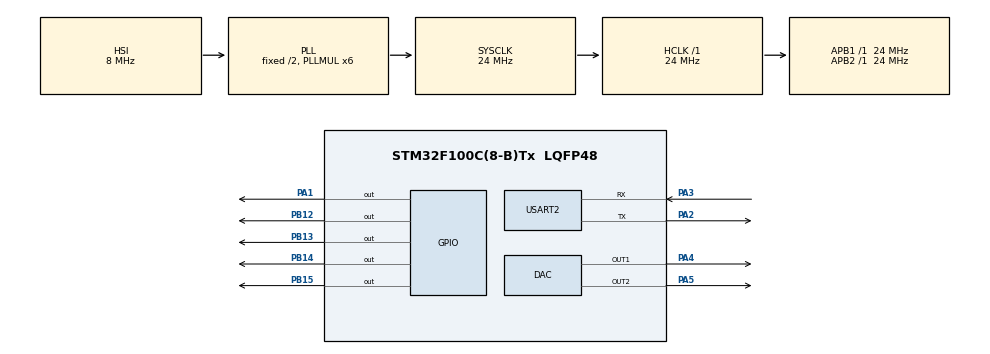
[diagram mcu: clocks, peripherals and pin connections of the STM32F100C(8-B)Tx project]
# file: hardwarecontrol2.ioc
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Dma.Request0=USART2_RX
Dma.Request1=USART2_TX
Dma.USART2_RX.0.Direction=DMA_PERIPH_TO_MEMORY
Dma.USART2_RX.0.Instance=DMA1_Channel6
Dma.USART2_RX.0.MemDataAlignment=DMA_MDATAALIGN_BYTE
Dma.USART2_RX.0.MemInc=DMA_MINC_ENABLE
Dma.USART2_RX.0.Mode=DMA_CIRCULAR
Dma.USART2_RX.0.PeriphDataAlignment=DMA_PDATAALIGN_BYTE
Dma.USART2_RX.0.PeriphInc=DMA_PINC_DISABLE
Dma.USART2_RX.0.Priority=DMA_PRIORITY_LOW
Dma.USART2_TX.1.Direction=DMA_MEMORY_TO_PERIPH
Dma.USART2_TX.1.Instance=DMA1_Channel7
Dma.USART2_TX.1.MemDataAlignment=DMA_MDATAALIGN_BYTE
Dma.USART2_TX.1.MemInc=DMA_MINC_ENABLE
Dma.USART2_TX.1.Mode=DMA_NORMAL
Dma.USART2_TX.1.PeriphDataAlignment=DMA_PDATAALIGN_BYTE
Dma.USART2_TX.1.PeriphInc=DMA_PINC_DISABLE
Dma.USART2_TX.1.Priority=DMA_PRIORITY_LOW
Mcu.Family=STM32F1
Mcu.Name=STM32F100C(8-B)Tx
Mcu.Package=LQFP48
NVIC.DMA1_Channel6_IRQn=true\:0\:0\:false\:false\:true\:false\:true\:true
NVIC.DMA1_Channel7_IRQn=true\:0\:0\:false\:false\:true\:false\:true\:true
NVIC.PriorityGroup=NVIC_PRIORITYGROUP_4
NVIC.RCC_IRQn=true\:0\:0\:false\:false\:true\:true\:false\:true
NVIC.TIM1_TRG_COM_TIM17_IRQn=true\:0\:0\:false\:false\:true\:true\:true\:true
NVIC.TIM1_UP_TIM16_IRQn=true\:0\:0\:false\:false\:true\:true\:true\:true
NVIC.TIM7_IRQn=true\:15\:0\:false\:false\:true\:false\:true\:true
NVIC.TimeBase=TIM7_IRQn
NVIC.TimeBaseIP=TIM7
NVIC.USART2_IRQn=true\:0\:0\:false\:false\:true\:true\:true\:true
PA1.Signal=GPIO_Output
PA13.Mode=Serial_Wire
PA13.Signal=SYS_JTMS-SWDIO
PA14.Mode=Serial_Wire
PA14.Signal=SYS_JTCK-SWCLK
PA2.Mode=Asynchronous
PA2.Signal=USART2_TX
PA3.Mode=Asynchronous
PA3.Signal=USART2_RX
PA4.Signal=COMP_DAC1_group
PA5.Signal=COMP_DAC2_group
PB12.Signal=GPIO_Output
PB13.Signal=GPIO_Output
PB14.Signal=GPIO_Output
PB15.Signal=GPIO_Output
PD0-OSC_IN.Mode=HSE-External-Oscillator
PD0-OSC_IN.Signal=RCC_OSC_IN
PD1-OSC_OUT.Mode=HSE-External-Oscillator
PD1-OSC_OUT.Signal=RCC_OSC_OUT
ProjectManager.HeapSize=0x400
ProjectManager.StackSize=0x400
ProjectManager.TargetToolchain=STM32CubeIDE
RCC.AHBFreq_Value=24000000
RCC.APB1Freq_Value=24000000
RCC.APB1TimFreq_Value=24000000
RCC.APB2Freq_Value=24000000
RCC.APB2TimFreq_Value=24000000
RCC.HCLKFreq_Value=24000000
RCC.PLLMUL=RCC_PLL_MUL6
RCC.SYSCLKFreq_VALUE=24000000
RCC.SYSCLKSource=RCC_SYSCLKSOURCE_PLLCLK
SH.COMP_DAC1_group.0=DAC_OUT1,DAC_OUT1
SH.COMP_DAC2_group.0=DAC_OUT2,DAC_OUT2
USART2.VirtualMode=VM_ASYNC
VP_SYS_VS_tim7.Mode=TIM7
VP_TIM16_VS_ClockSourceINT.Mode=Enable_Timer
VP_TIM17_VS_ClockSourceINT.Mode=Enable_Timer
board=custom

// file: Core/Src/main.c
/* USER CODE BEGIN Header */
/**
  ******************************************************************************
  * @file           : main.c
  * @brief          : Main program body
  ******************************************************************************
  * @attention
  *
  * Copyright (c) 2022 STMicroelectronics.
  * All rights reserved.
  *
  * This software is licensed under terms that can be found in the LICENSE file
  * in the root directory of this software component.
  * If no LICENSE file comes with this software, it is provided AS-IS.
  *
  ******************************************************************************
  */
/* USER CODE END Header */
#include "main.h"

/* USER CODE BEGIN Includes */
#include "kernel.h"
#include "soft_timer.h"
#include "communication_facade.h"
#include "movement_driver.h"
/* USER CODE END Includes */

DAC_HandleTypeDef hdac;

TIM_HandleTypeDef htim16;
TIM_HandleTypeDef htim17;

UART_HandleTypeDef huart2;
DMA_HandleTypeDef hdma_usart2_rx;
DMA_HandleTypeDef hdma_usart2_tx;

void SystemClock_Config(void);
static void MX_GPIO_Init(void);
static void MX_DAC_Init(void);
static void MX_TIM16_Init(void);
static void MX_DMA_Init(void);
static void MX_USART2_UART_Init(void);
static void MX_TIM17_Init(void);

int main(void)
{

  /* MCU Configuration--------------------------------------------------------*/

  /* Reset of all peripherals, Initializes the Flash interface and the Systick. */
  HAL_Init();

  /* Configure the system clock */
  SystemClock_Config();

  /* Initialize all configured peripherals */
  MX_GPIO_Init();
  MX_DAC_Init();
  MX_TIM16_Init();
  MX_DMA_Init();
  MX_USART2_UART_Init();
  MX_TIM17_Init();

  /* Infinite loop */
  /* USER CODE BEGIN WHILE */
  HAL_SetTickFreq(HAL_TICK_FREQ_1KHZ);
  communicationInit(&huart2, &hdma_usart2_rx, &hdma_usart2_tx);
  KERNEL_Init();
  MovementDriver_Init(&hdac);

  while (1) {

      invokePendingTimers();
      communicationInvoke();
	  KERNEL_Check();
    /* USER CODE END WHILE */

  }
}

void SystemClock_Config(void)
{
  RCC_OscInitTypeDef RCC_OscInitStruct = {0};
  RCC_ClkInitTypeDef RCC_ClkInitStruct = {0};

  /** Initializes the RCC Oscillators according to the specified parameters
  * in the RCC_OscInitTypeDef structure.
  */
  RCC_OscInitStruct.OscillatorType = RCC_OSCILLATORTYPE_HSI;
  RCC_OscInitStruct.HSIState = RCC_HSI_ON;
  RCC_OscInitStruct.HSICalibrationValue = RCC_HSICALIBRATION_DEFAULT;
  RCC_OscInitStruct.PLL.PLLState = RCC_PLL_ON;
  RCC_OscInitStruct.PLL.PLLSource = RCC_PLLSOURCE_HSI_DIV2;
  RCC_OscInitStruct.PLL.PLLMUL = RCC_PLL_MUL6;
  if (HAL_RCC_OscConfig(&RCC_OscInitStruct) != HAL_OK)
  {
    Error_Handler();
  }

  /** Initializes the CPU, AHB and APB buses clocks
  */
  RCC_ClkInitStruct.ClockType = RCC_CLOCKTYPE_HCLK|RCC_CLOCKTYPE_SYSCLK
                              |RCC_CLOCKTYPE_PCLK1|RCC_CLOCKTYPE_PCLK2;
  RCC_ClkInitStruct.SYSCLKSource = RCC_SYSCLKSOURCE_PLLCLK;
  RCC_ClkInitStruct.AHBCLKDivider = RCC_SYSCLK_DIV1;
  RCC_ClkInitStruct.APB1CLKDivider = RCC_HCLK_DIV1;
  RCC_ClkInitStruct.APB2CLKDivider = RCC_HCLK_DIV1;

  if (HAL_RCC_ClockConfig(&RCC_ClkInitStruct, FLASH_LATENCY_0) != HAL_OK)
  {
    Error_Handler();
  }
}

static void MX_DAC_Init(void)
{

  DAC_ChannelConfTypeDef sConfig = {0};

  /** DAC Initialization
  */
  hdac.Instance = DAC;
  if (HAL_DAC_Init(&hdac) != HAL_OK)
  {
    Error_Handler();
  }

  /** DAC channel OUT1 config
  */
  sConfig.DAC_Trigger = DAC_TRIGGER_NONE;
  sConfig.DAC_OutputBuffer = DAC_OUTPUTBUFFER_ENABLE;
  if (HAL_DAC_ConfigChannel(&hdac, &sConfig, DAC_CHANNEL_1) != HAL_OK)
  {
    Error_Handler();
  }

  /** DAC channel OUT2 config
  */
  if (HAL_DAC_ConfigChannel(&hdac, &sConfig, DAC_CHANNEL_2) != HAL_OK)
  {
    Error_Handler();
  }

}

static void MX_TIM16_Init(void)
{

  htim16.Instance = TIM16;
  htim16.Init.Prescaler = 0;
  htim16.Init.CounterMode = TIM_COUNTERMODE_UP;
  htim16.Init.Period = 65535;
  htim16.Init.ClockDivision = TIM_CLOCKDIVISION_DIV1;
  htim16.Init.RepetitionCounter = 0;
  htim16.Init.AutoReloadPreload = TIM_AUTORELOAD_PRELOAD_DISABLE;
  if (HAL_TIM_Base_Init(&htim16) != HAL_OK)
  {
    Error_Handler();
  }

}

static void MX_TIM17_Init(void)
{

  htim17.Instance = TIM17;
  htim17.Init.Prescaler = 0;
  htim17.Init.CounterMode = TIM_COUNTERMODE_UP;
  htim17.Init.Period = 65535;
  htim17.Init.ClockDivision = TIM_CLOCKDIVISION_DIV1;
  htim17.Init.RepetitionCounter = 0;
  htim17.Init.AutoReloadPreload = TIM_AUTORELOAD_PRELOAD_DISABLE;
  if (HAL_TIM_Base_Init(&htim17) != HAL_OK)
  {
    Error_Handler();
  }

}

static void MX_USART2_UART_Init(void)
{

  huart2.Instance = USART2;
  huart2.Init.BaudRate = 115200;
  huart2.Init.WordLength = UART_WORDLENGTH_8B;
  huart2.Init.StopBits = UART_STOPBITS_1;
  huart2.Init.Parity = UART_PARITY_NONE;
  huart2.Init.Mode = UART_MODE_TX_RX;
  huart2.Init.HwFlowCtl = UART_HWCONTROL_NONE;
  huart2.Init.OverSampling = UART_OVERSAMPLING_16;
  if (HAL_UART_Init(&huart2) != HAL_OK)
  {
    Error_Handler();
  }

}

static void MX_DMA_Init(void)
{

  /* DMA controller clock enable */
  __HAL_RCC_DMA1_CLK_ENABLE();

  /* DMA interrupt init */
  /* DMA1_Channel6_IRQn interrupt configuration */
  HAL_NVIC_SetPriority(DMA1_Channel6_IRQn, 0, 0);
  HAL_NVIC_EnableIRQ(DMA1_Channel6_IRQn);
  /* DMA1_Channel7_IRQn interrupt configuration */
  HAL_NVIC_SetPriority(DMA1_Channel7_IRQn, 0, 0);
  HAL_NVIC_EnableIRQ(DMA1_Channel7_IRQn);

}

static void MX_GPIO_Init(void)
{
  GPIO_InitTypeDef GPIO_InitStruct = {0};

  /* GPIO Ports Clock Enable */
  __HAL_RCC_GPIOD_CLK_ENABLE();
  __HAL_RCC_GPIOA_CLK_ENABLE();
  __HAL_RCC_GPIOB_CLK_ENABLE();

  /*Configure GPIO pin Output Level */
  HAL_GPIO_WritePin(GPIOA, GPIO_PIN_1, GPIO_PIN_RESET);

  /*Configure GPIO pin Output Level */
  HAL_GPIO_WritePin(GPIOB, GPIO_PIN_12|GPIO_PIN_13|GPIO_PIN_14|GPIO_PIN_15, GPIO_PIN_RESET);

  /*Configure GPIO pin : PA1 */
  GPIO_InitStruct.Pin = GPIO_PIN_1;
  GPIO_InitStruct.Mode = GPIO_MODE_OUTPUT_PP;
  GPIO_InitStruct.Pull = GPIO_NOPULL;
  GPIO_InitStruct.Speed = GPIO_SPEED_FREQ_LOW;
  HAL_GPIO_Init(GPIOA, &GPIO_InitStruct);

  /*Configure GPIO pins : PB12 PB13 PB14 PB15 */
  GPIO_InitStruct.Pin = GPIO_PIN_12|GPIO_PIN_13|GPIO_PIN_14|GPIO_PIN_15;
  GPIO_InitStruct.Mode = GPIO_MODE_OUTPUT_PP;
  GPIO_InitStruct.Pull = GPIO_NOPULL;
  GPIO_InitStruct.Speed = GPIO_SPEED_FREQ_LOW;
  HAL_GPIO_Init(GPIOB, &GPIO_InitStruct);

}

void HAL_TIM_PeriodElapsedCallback(TIM_HandleTypeDef *htim)
{
  if (htim->Instance == TIM7) {
    HAL_IncTick();
  }
}

void Error_Handler(void)
{
  __disable_irq();
  while (1)
  {
  }
}
